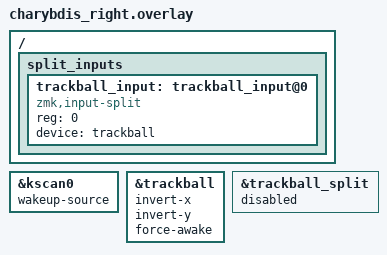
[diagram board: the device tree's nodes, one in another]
&kscan0 {
    wakeup-source;
};

&trackball {
    /* charybdis_3610.dtsi already defines irq-gpios/cpi/evt-type/x-y-input-code
     * for the badjeff pmw3610 driver. Only add overrides here. */
    invert-x;
    invert-y;
    /* Keep sensor awake while ZMK is ACTIVE; enter REST modes on IDLE/SLEEP. */
    force-awake;
};

&trackball_split {
    status = "disabled";
};

/ {
    split_inputs {
        trackball_input: trackball_input@0 {
            compatible = "zmk,input-split";
            reg = <0>;
            status = "okay";
            device = <&trackball>;
        };
    };
};
